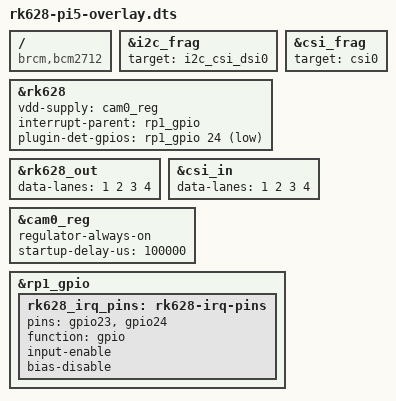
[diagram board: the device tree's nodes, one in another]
// SPDX-License-Identifier: GPL-2.0
/dts-v1/;
/plugin/;

#include "rk628-common.dtsi"

/ {
	compatible = "brcm,bcm2712";

	power_frag: fragment@2 {
		target = <&cam0_reg>;
		__overlay__ {
			status = "okay";
			regulator-always-on;
			startup-delay-us = <100000>;
		};
	};

	fragment@3 {
		target = <&rp1_gpio>;
		__overlay__ {
			rk628_irq_pins: rk628-irq-pins {
				pins = "gpio23", "gpio24";
				function = "gpio";
				input-enable;
				bias-disable;
			};
		};
	};

	__overrides__ {
		cam0 = <&i2c_frag>, "target:0=", <&i2c_csi_dsi0>,
		       <&csi_frag>, "target:0=", <&csi0>,
		       <&power_frag>, "target:0=", <&cam0_reg>,
		       <&rk628>, "vdd-supply:0=", <&cam0_reg>;
		cam1 = <&i2c_frag>, "target:0=", <&i2c_csi_dsi1>,
		       <&csi_frag>, "target:0=", <&csi1>,
		       <&power_frag>, "target:0=", <&cam1_reg>,
		       <&rk628>, "vdd-supply:0=", <&cam1_reg>;
	};
};

&i2c_frag {
	target = <&i2c_csi_dsi0>;
};

&csi_frag {
	target = <&csi0>;
};

&rk628 {
	vdd-supply = <&cam0_reg>;
	interrupt-parent = <&rp1_gpio>;
	plugin-det-gpios = <&rp1_gpio 24 1>; // GPIO24, active low
};

&rk628_out {
	data-lanes = <1 2 3 4>;
};

&csi_in {
	data-lanes = <1 2 3 4>;
};
